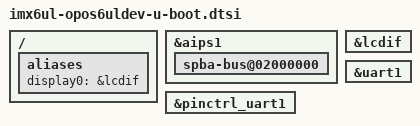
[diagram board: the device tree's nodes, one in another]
// SPDX-License-Identifier: GPL-2.0
/*
 * Device Tree Source extras for U-Boot for the OPOS6ULDev board
 *
 * Copyright (C) 2018 Armadeus Systems <support@armadeus.com>
 */

#include "imx6ul-opos6ul-u-boot.dtsi"

/ {
	aliases {
		display0 = &lcdif;
	};
};

&aips1 {
	bootph-pre-ram;

	spba-bus@02000000 {
		bootph-pre-ram;
	};
};

&lcdif {
	bootph-some-ram;
};

&pinctrl_uart1 {
	bootph-pre-ram;
};

&uart1 {
	bootph-pre-ram;
};
